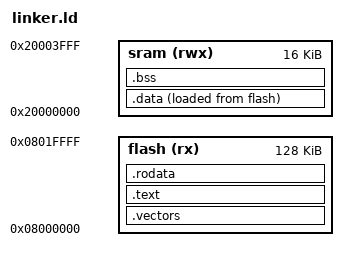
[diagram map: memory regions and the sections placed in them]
ENTRY(_reset);
/*
 This line tells the linker the value of the "entry point" attribute in the generated ELF header. This is an aid for a debugger (like Ozone, described below) that helps to set a breakpoint at the beginning of the firmware. A debugger does not know about a vector table, so it relies on the ELF header.
 */


MEMORY {
  flash(rx)  : ORIGIN = 0x08000000, LENGTH = 128k
  sram(rwx) : ORIGIN = 0x20000000, LENGTH = 16k  
}

_estack     = ORIGIN(sram) + LENGTH(sram);    /* initial stack pointer points to end of SRAM */

SECTIONS {

   .vectors  : { KEEP(*(.vectors)) }   > flash 
   /*The KEEP directive tells linker to preserve the .vectors section even if no symbols within it are directly referenced in the code 
    
    *Without KEEP, the linker may discard sections it believes are unused to optimize the binary size.
    
    */
   .text     : { *(.text*) }           > flash
   /*
    The syntax *(.text*) means "find all sections starting with .text in all input files."
    * */
   .rodata   : { *(.rodata*) }         > flash

     .data : {
    _sdata = .;   /* .data section start */
    *(.first_data)
    *(.data SORT(.data.*))
    /* SORT ensures a predictable and optimized memory layout */    
    /*
     With sorted sections, memory maps are more predictable and easier to read in map files (.map files generated by the linker), making debugging memory allocation issues more straightforward
     */

    _edata = .;  /* .data section end */
  } > sram AT > flash
  _srcdata = LOADADDR(.data);

    .bss : {
    _sbss = .;              /* .bss section start */
    *(.bss SORT(.bss.*) COMMON)

    /*The COMMON keyword is used in .bss to handle variables that are declared but not explicitly initialized (e.g., extern int z;). The linker merges all such symbols to avoid duplicate memory allocation.*/  

    _ebss = .;              /* .bss section end */
  } > sram


}

